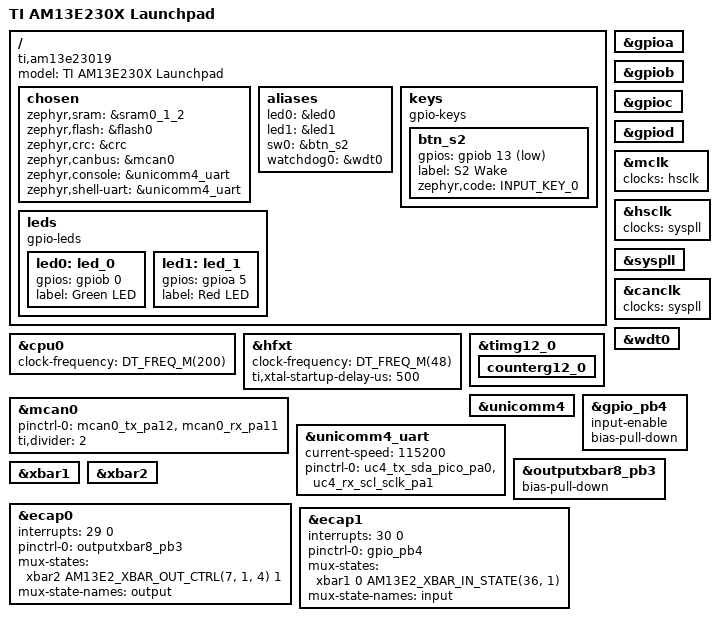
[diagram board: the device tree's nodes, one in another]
/*
 * Copyright (c) 2026 Texas Instruments Incorporated
 *
 * SPDX-License-Identifier: Apache-2.0
 */

/dts-v1/;

#include <ti/am13/am13e23019.dtsi>
#include <ti/am13/am13e23019-pinctrl.dtsi>
#include <zephyr/dt-bindings/gpio/gpio.h>
#include <zephyr/dt-bindings/input/input-event-codes.h>
#include <zephyr/dt-bindings/mux/ti_am13e2_xbar_in.h>
#include <zephyr/dt-bindings/mux/ti_am13e2_xbar_out.h>

/ {
	model = "TI AM13E230X Launchpad";
	compatible = "ti,am13e23019";

	chosen {
		zephyr,sram = &sram0_1_2;
		zephyr,flash = &flash0;
		zephyr,crc = &crc;
		zephyr,canbus = &mcan0;
		zephyr,console = &unicomm4_uart;
		zephyr,shell-uart = &unicomm4_uart;
	};

	aliases {
		led0 = &led0;
		led1 = &led1;
		sw0 = &btn_s2;
		watchdog0 = &wdt0;
	};

	keys {
		compatible = "gpio-keys";

		btn_s2: btn_s2 {
			gpios = <&gpiob 13 (GPIO_ACTIVE_LOW | GPIO_PULL_UP)>;
			label = "S2 Wake";
			zephyr,code = <INPUT_KEY_0>;
		};
	};

	leds {
		compatible = "gpio-leds";

		led0: led_0 {
			gpios = <&gpiob 0 GPIO_ACTIVE_HIGH>;
			label = "Green LED";
		};

		led1: led_1 {
			gpios = <&gpioa 5 GPIO_ACTIVE_HIGH>;
			label = "Red LED";
		};
	};
};

&gpioa {
	status = "okay";
};

&gpiob {
	status = "okay";
};

&gpioc {
	status = "okay";
};

&gpiod {
	status = "okay";
};

&cpu0 {
	clock-frequency = <DT_FREQ_M(200)>;
};

&mclk {
	clocks = <&hsclk>;
};

&hsclk {
	clocks = <&syspll>;
	status = "okay";
};

&syspll {
	status = "okay";
};

&hfxt {
	clock-frequency = <DT_FREQ_M(48)>;
	ti,xtal-startup-delay-us = <500>;
};

&timg12_0 {
	status = "okay";

	counterg12_0: counterg12_0 {
		status = "okay";
	};
};

&canclk {
	clocks = <&syspll>;
	status = "okay";
};

&mcan0 {
	status = "okay";
	pinctrl-0 = <&mcan0_tx_pa12 &mcan0_rx_pa11>;
	pinctrl-names = "default";
	ti,divider = <2>;
};

&wdt0 {
	status = "okay";
};

&unicomm4 {
	status = "okay";
};

&unicomm4_uart {
	status = "okay";
	current-speed = <115200>;
	pinctrl-0 = <&uc4_tx_sda_pico_pa0 &uc4_rx_scl_sclk_pa1>;
	pinctrl-names = "default";
};

&gpio_pb4 {
	input-enable;
	bias-pull-down;
};

&outputxbar8_pb3 {
	bias-pull-down;
};

&xbar1 {
	status = "okay";
};

&xbar2 {
	status = "okay";
};

&ecap0 {
	status = "okay";
	interrupts = <29 0>;
	pinctrl-0 = <&outputxbar8_pb3>;
	pinctrl-names = "default";

	/* ECAP0 -> OUTPUTXBAR8 (idx 7) -> G1SEL bit 4 -> PB3 */
	mux-states = <&xbar2 AM13E2_XBAR_OUT_CTRL(7, 1, 4) 1>;
	mux-state-names = "output";
};

&ecap1 {
	status = "okay";
	interrupts = <30 0>;
	pinctrl-0 = <&gpio_pb4>;
	pinctrl-names = "default";

	/* PB4 (GPIO36) -> INPUTXBAR1 -> ECAP1 ECCTL0.INPUTSEL (raw=1) */
	mux-states = <&xbar1 0 AM13E2_XBAR_IN_STATE(36, 1)>;
	mux-state-names = "input";
};
